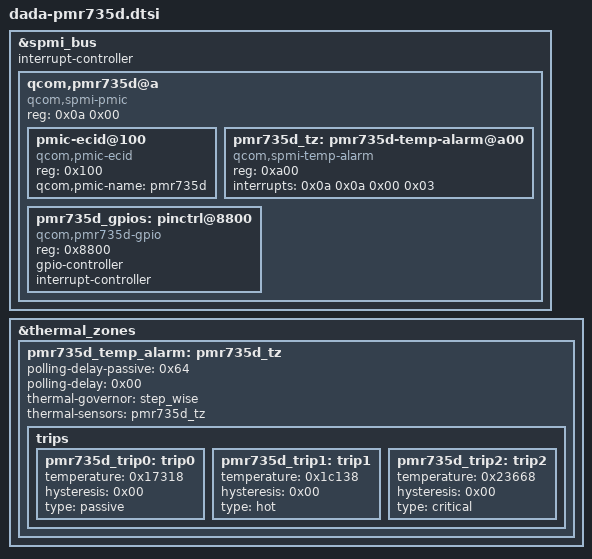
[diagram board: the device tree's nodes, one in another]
// SPDX-License-Identifier: BSD-3-Clause
/*
 * Copyright (c) 2023-2024 Qualcomm Innovation Center, Inc. All rights reserved.
 * Copyright (c) 2025 The LineageOS Project
 */

&spmi_bus {
	#address-cells = <0x02>;
	#size-cells = <0x00>;
	interrupt-controller;
	#interrupt-cells = <0x04>;

	qcom,pmr735d@a {
		compatible = "qcom,spmi-pmic";
		reg = <0x0a 0x00>;
		#address-cells = <0x01>;
		#size-cells = <0x00>;

		pmic-ecid@100 {
			compatible = "qcom,pmic-ecid";
			reg = <0x100>;
			qcom,pmic-name = "pmr735d";
		};

		pmr735d_tz: pmr735d-temp-alarm@a00 {
			compatible = "qcom,spmi-temp-alarm";
			reg = <0xa00>;
			interrupts = <0x0a 0x0a 0x00 0x03>;
			#thermal-sensor-cells = <0x00>;
		};

		pmr735d_gpios: pinctrl@8800 {
			compatible = "qcom,pmr735d-gpio";
			reg = <0x8800>;
			gpio-controller;
			#gpio-cells = <0x02>;
			interrupt-controller;
			#interrupt-cells = <0x02>;
		};
	};
};

&thermal_zones {
	pmr735d_temp_alarm: pmr735d_tz {
		polling-delay-passive = <0x64>;
		polling-delay = <0x00>;
		thermal-governor = "step_wise";
		thermal-sensors = <&pmr735d_tz>;

		trips {

			pmr735d_trip0: trip0 {
				temperature = <0x17318>;
				hysteresis = <0x00>;
				type = "passive";
			};

			pmr735d_trip1: trip1 {
				temperature = <0x1c138>;
				hysteresis = <0x00>;
				type = "hot";
			};

			pmr735d_trip2: trip2 {
				temperature = <0x23668>;
				hysteresis = <0x00>;
				type = "critical";
			};
		};
	};
};
